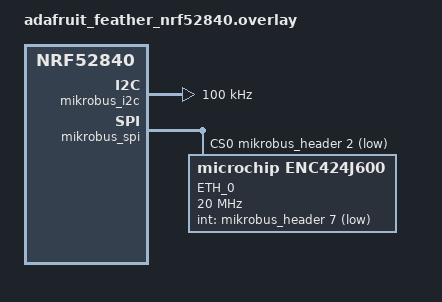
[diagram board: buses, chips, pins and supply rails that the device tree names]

/*
 * Copyright (c) 2020 Vestas Wind Systems A/S
 *
 * SPDX-License-Identifier: Apache-2.0
 */

// &mikrobus_spi {
// 	status = "okay";

// 	// click_spi2: spi-device@1 {
// 	// 	compatible = "microchip,mcp3204";
// 	// 	reg = <0x1>;
// 	// 	spi-max-frequency = <100000>;
// 	// 	label = "MCP3201";
// 	// 	#io-channel-cells = <1>;
// 	// };


// };

// not needed but fixes upstream dts
&mikrobus_i2c {
	status = "okay";
	clock-frequency = <I2C_BITRATE_STANDARD>;
};

&mikrobus_spi {
	status = "okay";
	cs-gpios = <&mikrobus_header 2 GPIO_ACTIVE_LOW>;	/* A5 */

	enc424j600@0 {
		status = "okay";
		compatible = "microchip,enc424j600";
		reg = <0>;
		spi-max-frequency = <20000000>;
		int-gpios = <&mikrobus_header 7 GPIO_ACTIVE_LOW>;	/* PIO1_28 => PLU_IN3  */
		label = "ETH_0";
	};
};

